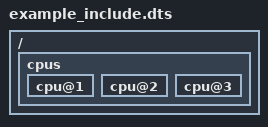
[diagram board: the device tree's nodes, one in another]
/include/ "system-conf.dtsi"
/include/ "xen.dtsi"
/ {
     cpus {
         cpu@1 {
             device_type = "none";
         };
         cpu@2 {
             device_type = "none";
         };
         cpu@3 {
             device_type = "none";
         };
     };
 };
